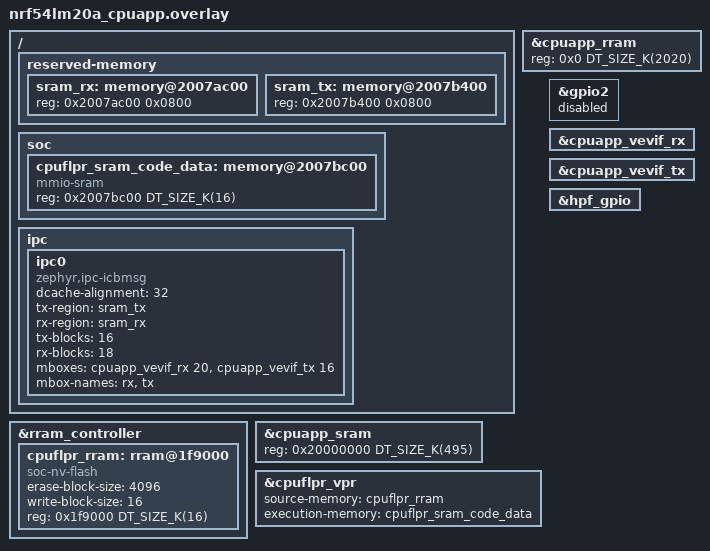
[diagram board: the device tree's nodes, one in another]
/*
 * Copyright (c) 2025 Nordic Semiconductor ASA
 *
 * SPDX-License-Identifier: LicenseRef-Nordic-5-Clause
 */

#include "../../hpf-gpio-app.overlay"

/ {
	reserved-memory {
		#address-cells = <1>;
		#size-cells = <1>;

		sram_rx: memory@2007ac00 {
			reg = <0x2007ac00 0x0800>;
		};

		sram_tx: memory@2007b400 {
			reg = <0x2007b400 0x0800>;
		};
	};

	soc {
		cpuflpr_sram_code_data: memory@2007bc00 {
			compatible = "mmio-sram";
			reg = <0x2007bc00 DT_SIZE_K(16)>;
			#address-cells = <1>;
			#size-cells = <1>;
			ranges = <0x0 0x2007bc00 DT_SIZE_K(16)>;
		};
	};

	ipc {
		ipc0: ipc0 {
			compatible = "zephyr,ipc-icbmsg";
			dcache-alignment = <32>;
			tx-region = <&sram_tx>;
			rx-region = <&sram_rx>;
			tx-blocks = <16>;
			rx-blocks = <18>;
			mboxes = <&cpuapp_vevif_rx 20>, <&cpuapp_vevif_tx 16>;
			mbox-names = "rx", "tx";
			status = "okay";
		};
	};
};

&rram_controller {
	cpuflpr_rram: rram@1f9000 {
		compatible = "soc-nv-flash";
		erase-block-size = <4096>;
		write-block-size = <16>;
		reg = <0x1f9000 DT_SIZE_K(16)>;
		ranges = <0x0 0x1f9000 DT_SIZE_K(16)>;
		#address-cells = <1>;
		#size-cells = <1>;
	};
};

&cpuapp_rram {
	reg = <0x0 DT_SIZE_K(2020)>;
};

&cpuapp_sram {
	reg = <0x20000000 DT_SIZE_K(495)>;
	ranges = <0x0 0x20000000 DT_SIZE_K(495)>;
};

&cpuflpr_vpr {
	source-memory = <&cpuflpr_rram>;
	execution-memory = <&cpuflpr_sram_code_data>;
};

&gpio2 {
	status = "disabled";
};

&cpuapp_vevif_rx {
	status = "okay";
};

&cpuapp_vevif_tx {
	status = "okay";
};

&hpf_gpio {
	status = "okay";
};
